# EOS-S3 register map
File version: 0.1
CPU: CM4 r0p1, selectable endian, MPU, FPU, 3 interrupt priority bits
Registers are 32-bit, read-write, reset 0x0 unless marked. A register's access mark holds for its fields unless they carry their own. Offsets are from the block's base; [hi:lo] are bit positions; {n}, {i} and the like mark numbered series; 'fields as' and 'values as' point back to an identical list.

## ExtRegsFFE — Flexible Fusion Engine registers
Base 0x4004A000
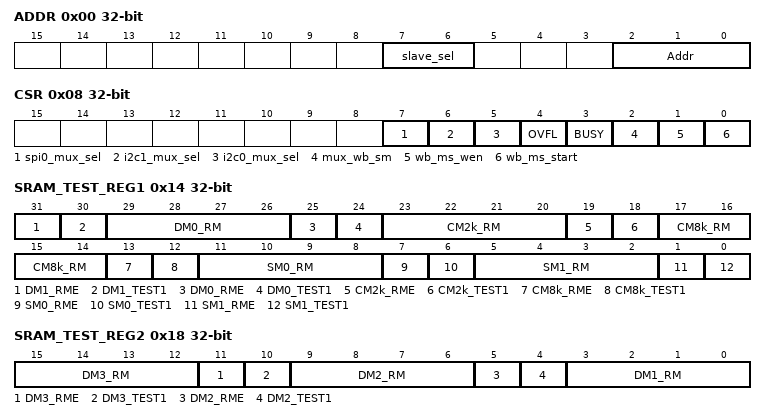
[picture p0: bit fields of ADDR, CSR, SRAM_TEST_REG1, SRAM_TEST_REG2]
0x00 ADDR — Wishbone master address selection
  [7:6] slave_sel — MSB to select which which slave accessed by WB master
    0=i2c_0 (Select i2c_0 as the sensor that will be accessed by the Wishbone Master); 1=i2c_1 (Select i2c_1 as the sensor that will be accessed by the Wishbone Master); 2=spi_0 (Select spi_0 as the sensor that will be accessed by the Wishbone Master)
  [2:0] Addr — Slave address register via Wishbone master
0x04 WDATA — I2C slave data register via WishBone master
  [7:0] WDATA — I2C slave data via WB
0x08 CSR — Control and status register
  [7] spi0_mux_sel — spi_0 wishbone control mux select
    0=sm1_as_controller (Let SM1 control the port.); 1=wb_master_as_controller (Let Wishbone Master control the port)
  [6] i2c1_mux_sel — I2C_1 wishbone control mux select
    values as spi0_mux_sel
  [5] i2c0_mux_sel — I2C_0 wishbone control mux select
    values as spi0_mux_sel
  [4] OVFL ro — Indicates if there's a FFE push operation overflow
  [3] BUSY ro — Indicates if the Wishbone is busy
  [2] mux_wb_sm wo — Mux select between SM and WB masters.
    0=sm_wishbone_master (Select SM WB Master.); 1=wishbone_master (Select WB Master.)
  [1] wb_ms_wen — Wishbone master write enable.
    0=read; 1=write
  [0] wb_ms_start — Wishbone master start transactions. This bit is self clearing.
0x0C RDATA — Read data from I2C to Wishbone master is registered
  [7:0] RDATA
0x14 SRAM_TEST_REG1 — SRAM Test control register 1
  [31] DM1_RME — DM1_RME control for FFE SRAM
  [30] DM1_TEST1 — DM1_TEST1 control for FFE SRAM
  [29:26] DM0_RM — DM0_RM control for FFE SRAM
  [25] DM0_RME — DM0_RME control for FFE SRAM
  [24] DM0_TEST1 — DM0_TEST1 control for FFE SRAM
  [23:20] CM2k_RM — CM2k_RM control for FFE SRAM
  [19] CM2k_RME — CM2k_RME control for FFE SRAM
  [18] CM2k_TEST1 — CM2k_TEST1 control for FFE SRAM
  [17:14] CM8k_RM — CM8k_RM control for FFE SRAM
  [13] CM8k_RME — CM8k_RME control for FFE SRAM
  [12] CM8k_TEST1 — CM8k_TEST1 control for FFE SRAM
  [11:8] SM0_RM — SM0_RM control for FFE SRAM
  [7] SM0_RME — SM0_RME control for FFE SRAM
  [6] SM0_TEST1 — SM0_TEST1 control for FFE SRAM
  [5:2] SM1_RM — SM1_RM control for FFE SRAM
  [1] SM1_RME — SM1_RME control for FFE SRAM
  [0] SM1_TEST1 — SM1_TEST1 control for FFE SRAM
0x18 SRAM_TEST_REG2 — SRAM Test control register 2
  [15:12] DM3_RM — DM3_RM control for FFE SRAM
  [11] DM3_RME — DM3_RME control for FFE SRAM
  [10] DM3_TEST1 — DM3_TEST1 control for FFE SRAM
  [9:6] DM2_RM — DM0_RM control for FFE SRAM
  [5] DM2_RME — DM2_RME control for FFE SRAM
  [4] DM2_TEST1 — DM2_TEST1 control for FFE SRAM
  [3:0] DM1_RM — DM0_RM control for FFE SRAM
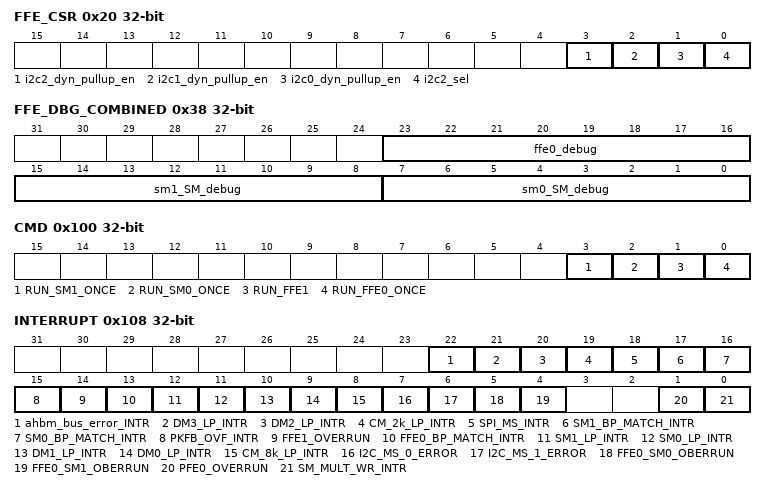
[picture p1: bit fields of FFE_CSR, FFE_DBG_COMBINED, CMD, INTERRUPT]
0x20 FFE_CSR — Flexible Fusion Engine status and control register
  [3] i2c2_dyn_pullup_en — i2c2 dynamic pull-up enable
  [2] i2c1_dyn_pullup_en — i2c1 dynamic pull-up enable
  [1] i2c0_dyn_pullup_en — i2c0 dynamic pull-up enable
  [0] i2c2_sel — Select wich i2c is taken as i2c
    0=i2c1 (Select i2c1 as i2c2); 1=i2c2 (Select i2c2 as i2c2)
0x38 FFE_DBG_COMBINED — Combined Flexible Fusion Engine debug signals
  [23:16] ffe0_debug ro — ffe0 debug signals
  [15:8] sm1_SM_debug ro — Sensor memory 1 debug signals
  [7:0] sm0_SM_debug ro — Sensor memory 0 debug signals
0x100 CMD — Commands for the Flexible Fusion Engine
  [3] RUN_SM1_ONCE wo — When a '1' is written to this location, causes the SM1 to run once; reads as 0
  [2] RUN_SM0_ONCE wo — When a '1' is written to this location, causes the SM0 to run once; reads as 0
  [1] RUN_FFE1 wo — When a '1' is written to this location, causes the FFE1 to start; reads as 0
  [0] RUN_FFE0_ONCE wo — When a '1' is written to this location, causes the FFE to execute one complete run of its algorithm; reads as 0
0x108 INTERRUPT — Varied interrupt configurations
  [22] ahbm_bus_error_INTR — This bit is set when there is a bus error on the AHB bus (HRESP=1).
  [21] DM3_LP_INTR — This bit is set when there is an access to the memory while it is in low power (deep sleep or shut down)
  [20] DM2_LP_INTR — This bit is set when there is an access to the memory while it is in low power (deep sleep or shut down)
  [19] CM_2k_LP_INTR — This bit is set when there is an access to the memory while it is in low power (deep sleep or shut down)
  [18] SPI_MS_INTR — This bit is set when there is an interrupt request from SPI_MS for sensor
  [17] SM1_BP_MATCH_INTR — This bit is set when there is a break point match in SM1
  [16] SM0_BP_MATCH_INTR — This bit is set when there is a break point match in SM0
  [15] PKFB_OVF_INTR — This bit is set when the FFE pushes to the PKFB causing an overflow
  [14] FFE1_OVERRUN — This bit is set when the FFE does not complete the algorithm by the time the next sample period begins.
  [13] FFE0_BP_MATCH_INTR — This bit is set when there is a break point match in FFE0
  [12] SM1_LP_INTR — This bit is set when there is an access to the memory while it is in low power (deep sleep or shut down)
  [11] SM0_LP_INTR — This bit is set when there is an access to the memory while it is in low power (deep sleep or shut down)
  [10] DM1_LP_INTR — This bit is set when there is an access to the memory while it is in low power (deep sleep or shut down)
  [9] DM0_LP_INTR — This bit is set when there is an access to the memory while it is in low power (deep sleep or shut down)
  [8] CM_8k_LP_INTR — This bit is set when there is an access to the memory while it is in low power (deep sleep or shut down)
  [7] I2C_MS_0_ERROR — This bit is set when the I2C Master receives a NACK when transmitting a device address. The I2C Master is used by the Sensor Manager to retrieve sensor data.
  [6] I2C_MS_1_ERROR — This bit is set when the I2C Master receives a NACK when transmitting a device address. The I2C Master is used by the Sensor Manager to retrieve sensor data.
  [5] FFE0_SM0_OBERRUN — This bit is set when the SM does not complete the algorithm by the time the next sample period begins. This bit can only be cleared by issuing a device reset (software reset, or global reset via the Reset pin).
  [4] FFE0_SM1_OBERRUN — This bit is set when the SM does not complete the algorithm by the time the next sample period begins. This bit can only be cleared by issuing a device reset (software reset, or global reset via the Reset pin).
  [1] PFE0_OVERRUN — This bit is set when the FFE does not complete the algorithm by the time the next sample period begins. This bit can only be cleared by issuing a device reset (software reset, or global reset via the Reset pin).
  [0] SM_MULT_WR_INTR — This bit is set when an FFE tries to write to more that one FIFO simultaneously. The FIFO PUSH value must be one hot, with only one pushd asserted.
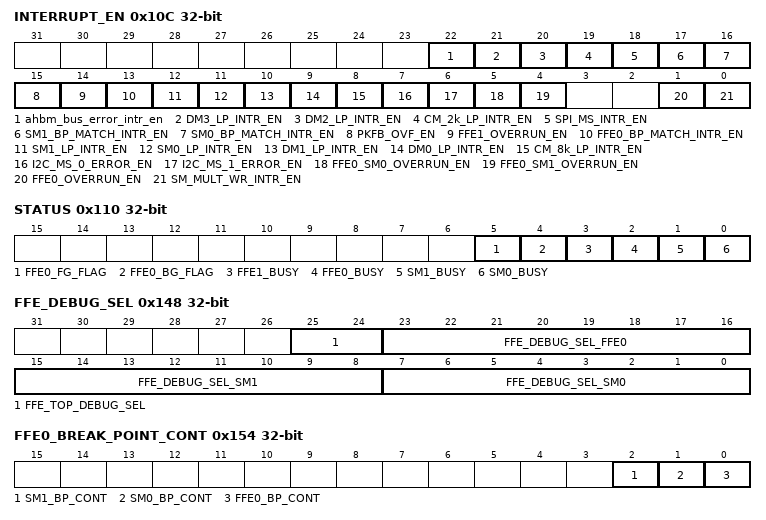
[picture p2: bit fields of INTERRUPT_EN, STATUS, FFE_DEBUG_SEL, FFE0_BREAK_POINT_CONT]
0x10C INTERRUPT_EN — Control the masking for different Flexible Fusion Engine interrupts
  [all] fields
    0=Mask the interrupt event; 1=Unmask the interrupt event
  [22] ahbm_bus_error_intr_en — Set to enable the interrupt, leave cleared to mask
  [21] DM3_LP_INTR_EN — Set to enable the interrupt, leave cleared to mask
  [20] DM2_LP_INTR_EN — Set to enable the interrupt, leave cleared to mask
  [19] CM_2k_LP_INTR_EN — Set to enable the interrupt, leave cleared to mask
  [18] SPI_MS_INTR_EN — Set to enable the interrupt, leave cleared to mask
  [17] SM1_BP_MATCH_INTR_EN — Set to enable the interrupt, leave cleared to mask
  [16] SM0_BP_MATCH_INTR_EN — Set to enable the interrupt, leave cleared to mask
  [15] PKFB_OVF_EN — Set to enable the interrupt, leave cleared to mask
  [14] FFE1_OVERRUN_EN — Set to enable the interrupt, leave cleared to mask
  [13] FFE0_BP_MATCH_INTR_EN — Set to enable the interrupt, leave cleared to mask
  [12] SM1_LP_INTR_EN — Set to enable the interrupt, leave cleared to mask
  [11] SM0_LP_INTR_EN — Set to enable the interrupt, leave cleared to mask
  [10] DM1_LP_INTR_EN — Set to enable the interrupt, leave cleared to mask
  [9] DM0_LP_INTR_EN — Set to enable the interrupt, leave cleared to mask
  [8] CM_8k_LP_INTR_EN — Set to enable the interrupt, leave cleared to mask
  [7] I2C_MS_0_ERROR_EN — Set to enable the interrupt, leave cleared to mask
  [6] I2C_MS_1_ERROR_EN — Set to enable the interrupt, leave cleared to mask
  [5] FFE0_SM0_OVERRUN_EN — Set to enable the interrupt, leave cleared to mask
  [4] FFE0_SM1_OVERRUN_EN — Set to enable the interrupt, leave cleared to mask
  [1] FFE0_OVERRUN_EN — Set to enable the interrupt, leave cleared to mask
  [0] SM_MULT_WR_INTR_EN — Set to enable the interrupt, leave cleared to mask
0x110 STATUS — FFE status register
  [5] FFE0_FG_FLAG — This is the ffe0 background thread status
  [4] FFE0_BG_FLAG — This is the ffe0 background thread status
  [3] FFE1_BUSY — This bit is set whenever the FFE1 is busy.
  [2] FFE0_BUSY — This bit is set whenever the FFE0 is busy.
  [1] SM1_BUSY ro — This bit is set whenever the Sensor Manager is busy.
  [0] SM0_BUSY ro — This bit is set whenever the Sensor Manager is busy.
0x114 MAILBOX_TO_FFE0 — Mailbox register to the FFE. This register can be set by system software to send a message or configuration information to the FFE as it runs its algorithm, thus affecting the algorithm while it is running. A special instruction may be used in the algorithm to read this mailbox register.
0x120 SM_RUNTIME_ADDR — SM0/SM1 run time address
  [9:0] SM_RUNTIME_ADDR
0x124 SM0_RUNTIME_ADDR_CTRL — Used to toggle signal used to signal when a new value has been written.
  [0] SM0_RUNTIME_ADDR_CTRL — Write a '1' to Toggle signal used to signal when a new value has been written
0x128 SM1_RUNTIME_ADDR_CTRL — Used to toggle signal used to signal when a new value has been written.
  [0] SM1_RUNTIME_ADDR_CTRL — Write a '1' to Toggle signal used to signal when a new value has been written
0x12C SM0_RUNTIME_ADDR_CUR — SM current program counter
  [9:0] SM0_RUNTIME_ADDR_CUR
0x130 SM1_RUNTIME_ADDR_CUR — SM current program counter
  [9:0] SM1_RUNTIME_ADDR_CUR
0x140 SM0_DEBUG_SEL — SM Debug selection
  [7:0] SM0_DEBUG_SEL
0x144 SM1_DEBUG_SEL — SM Debug selection
  [7:0] SM1_DEBUG_SEL
0x148 FFE_DEBUG_SEL (reset mask 0xFFFFFF) — Debug Selection
  [25:24] FFE_TOP_DEBUG_SEL — FFE_TOP_MS debug slection
    0=sm0 (Select sm0); 1=sm1 (Select sm1); 2=ffe0 (Select ffe0)
  [23:16] FFE_DEBUG_SEL_FFE0 — FFE0 LS debug slection
  [15:8] FFE_DEBUG_SEL_SM1 — SM1 LS debug slection
  [7:0] FFE_DEBUG_SEL_SM0 — SM0 LS debug slection
0x150 FFE0_BREAK_POINT_CFG — Break point control
  [1] FFE0_FORCE_STOP — This causes the FFE to immediately halt execution.
  [1] FFE0_BreakPt_Sw-Brk — Causes the signal to toggle when written with a '1' in this bit position.
  [0] FFE0_BP_EN — break point execution -- 0 : Disabled -- 1 : Enabled
0x154 FFE0_BREAK_POINT_CONT — Seems to be another breakpoint control register
  [2] SM1_BP_CONT — This is a single, host controlled input toggle signal, Break Point Match Continue. Software uses this toggle signal to resume code execution from the Break Point condition.
  [1] SM0_BP_CONT — This is a single, host controlled input toggle signal, Break Point Match Continue. Software uses this toggle signal to resume code execution from the Break Point condition.
  [0] FFE0_BP_CONT — This restarts FFE code execution following a pause due to reaching a 'break point'.
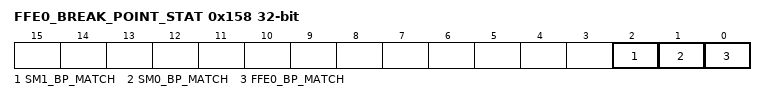
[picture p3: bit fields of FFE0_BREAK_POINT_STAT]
0x158 FFE0_BREAK_POINT_STAT — FFE break point status register
  [2] SM1_BP_MATCH ro — SM Break Point Match signal output to the host that notifies the host that the break point condition has been detected.
  [1] SM0_BP_MATCH ro — SM Break Point Match signal output to the host that notifies the host that the break point condition has been detected.
  [0] FFE0_BP_MATCH ro — This signals that a 'break point' has been reached and FFE execution is paused.
{0x160+4i} FFE0_BP_XPC_{i} (i=0..3) — These registers hold the xPC (program counter) address 'break points'.
  [13:0] FFE0_BP_XPC_{i}
